# EFR32MG1B register map
File version: 5.4.0
Silicon Labs EFR32MG1B Cortex-M MCU
Registers are 32-bit, read-write, reset 0x0 unless marked. A register's access mark holds for its fields unless they carry their own. Offsets are from the block's base; lines under a group give offsets from that group; [hi:lo] are bit positions; {n}, {i} and the like mark numbered series; 'fields as' and 'values as' point back to an identical list; <NAME> marks a mode.

## Memory map
0x40000000 ACMP0 size 0x400
0x40000400 ACMP1 size 0x400
0x40002000 ADC0 size 0x400
0x40006000 IDAC0 size 0x400
0x4000A000 GPIO size 0x1000
0x4000C000 I2C0 size 0x400
0x40010000 USART0 size 0x400
0x40010400 USART1 size 0x400
0x40018000 TIMER0 size 0x400
0x40018400 TIMER1 size 0x400
0x4001C000 GPCRC size 0x400
0x4001E000 CRYOTIMER size 0x400
0x40042000 RTCC size 0x400
0x40046000 LETIMER0 size 0x400
0x4004A000 LEUART0 size 0x400
0x4004E000 PCNT0 size 0x400
0x40052000 WDOG0 size 0x400
0x400E0000 MSC size 0x800
0x400E1000 FPUEH size 0x400
0x400E2000 LDMA size 0x1000
0x400E3000 EMU size 0x400
0x400E4000 CMU size 0x400
0x400E5000 RMU size 0x400
0x400E6000 PRS size 0x400
0x400F0000 CRYPTO size 0x400

## Interrupts
0 EMU
2 WDOG0
8 LDMA
9 GPIO_EVEN (GPIO)
10 TIMER0
11 USART0_RX (USART0)
12 USART0_TX (USART0)
13 ACMP0 (ACMP0, ACMP1)
14 ADC0
15 IDAC0
16 I2C0
17 GPIO_ODD (GPIO)
18 TIMER1
19 USART1_RX (USART1)
20 USART1_TX (USART1)
21 LEUART0
22 PCNT0
23 CMU
24 MSC
25 CRYPTO
26 LETIMER0
29 RTCC
31 CRYOTIMER
33 FPUEH

## Further device data
name=Copyright 2017 Silicon Laboratories, Inc., flashBaseAddress=0x00000000, flashAccessTypes=rx, sramBaseAddress=0x20000000, sramAccessTypes=rwx

## RMU
Base 0x400E5000
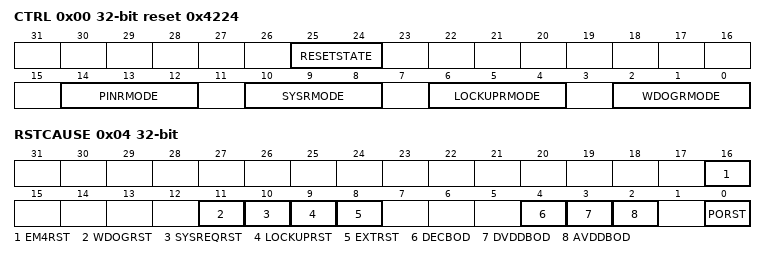
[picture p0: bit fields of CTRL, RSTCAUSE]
0x00 CTRL reset 0x4224 — Control Register
  [25:24] RESETSTATE — System Software Reset State
  [14:12] PINRMODE — PIN Reset Mode
    0=DISABLED (Reset request is blocked.); 1=LIMITED (The CRYOTIMER, DEBUGGER, RTCC, are not reset.); 2=EXTENDED (The CRYOTIMER, DEBUGGER are not reset. RTCC is reset.); 4=FULL (The entire device is reset except some EMU and RMU registers.)
  [10:8] SYSRMODE — Core Sysreset Reset Mode
    values as PINRMODE
  [6:4] LOCKUPRMODE — Core LOCKUP Reset Mode
    values as PINRMODE
  [2:0] WDOGRMODE — WDOG Reset Mode
    0=DISABLED (Reset request is blocked. This disable bit is redundant with enable/disable bit in WDOG); 1=LIMITED (The CRYOTIMER, DEBUGGER, RTCC, are not reset.); 2=EXTENDED (The CRYOTIMER, DEBUGGER are not reset. RTCC is reset.); 4=FULL (The entire device is reset except some EMU and RMU registers.)
0x04 RSTCAUSE ro — Reset Cause Register
  [16] EM4RST — EM4 Reset
  [11] WDOGRST — Watchdog Reset
  [10] SYSREQRST — System Request Reset
  [9] LOCKUPRST — LOCKUP Reset
  [8] EXTRST — External Pin Reset
  [4] DECBOD — Brown Out Detector Decouple Domain Reset
  [3] DVDDBOD — Brown Out Detector DVDD Reset
  [2] AVDDBOD — Brown Out Detector AVDD Reset
  [0] PORST — Power on Reset
0x08 CMD wo — Command Register
  [0] RCCLR — Reset Cause Clear
0x0C RST reset not defined — Reset Control Register
0x10 LOCK — Configuration Lock Register
  [15:0] LOCKKEY — Configuration Lock Key
    0=UNLOCKED; 1=LOCKED

## PRS
Base 0x400E6000
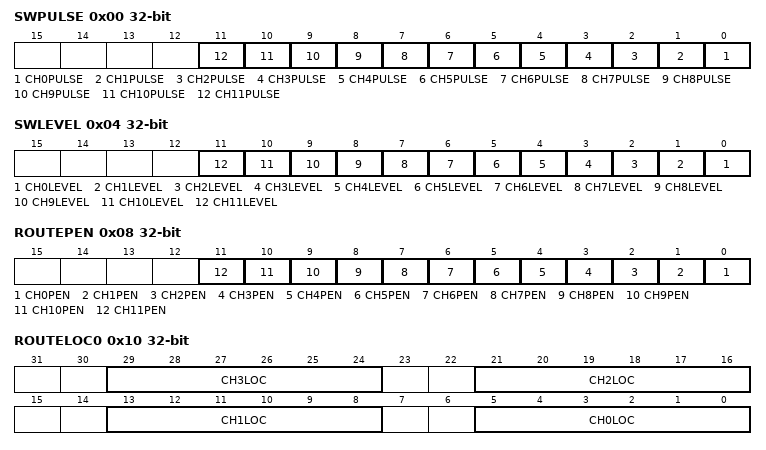
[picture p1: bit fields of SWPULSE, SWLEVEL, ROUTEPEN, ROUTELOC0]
0x00 SWPULSE wo — Software Pulse Register
  [n] CH{n}PULSE (n=0..11) — Channel {n} Pulse Generation
0x04 SWLEVEL — Software Level Register
  [n] CH{n}LEVEL (n=0..11) — Channel {n} Software Level
0x08 ROUTEPEN — I/O Routing Pin Enable Register
  [n] CH{n}PEN (n=0..11) — CH{n} Pin Enable
0x10 ROUTELOC0 — I/O Routing Location Register
  [29:24] CH3LOC — I/O Location
    {v}=LOC{v} (Location {v}) (v=0..14)
  [21:16] CH2LOC — I/O Location
    {v}=LOC{v} (Location {v}) (v=0..7)
  [13:8] CH1LOC — I/O Location
    {v}=LOC{v} (Location {v}) (v=0..7)
  [5:0] CH0LOC — I/O Location
    {v}=LOC{v} (Location {v}) (v=0..13)
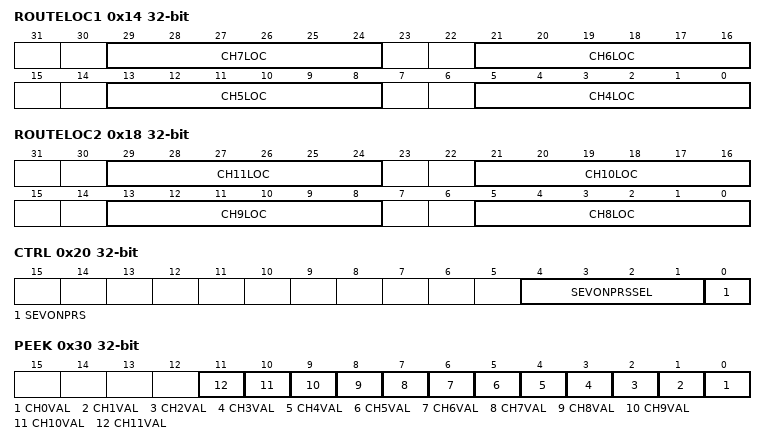
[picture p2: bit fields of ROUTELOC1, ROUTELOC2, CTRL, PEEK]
0x14 ROUTELOC1 — I/O Routing Location Register
  [29:24] CH7LOC — I/O Location
    {v}=LOC{v} (Location {v}) (v=0..10)
  [21:16] CH6LOC — I/O Location
    {v}=LOC{v} (Location {v}) (v=0..17)
  [13:8] CH5LOC — I/O Location
    {v}=LOC{v} (Location {v}) (v=0..6)
  [5:0] CH4LOC — I/O Location
    {v}=LOC{v} (Location {v}) (v=0..6)
0x18 ROUTELOC2 — I/O Routing Location Register
  [29:24] CH11LOC — I/O Location
    {v}=LOC{v} (Location {v}) (v=0..5)
  [21:16] CH10LOC — I/O Location
    {v}=LOC{v} (Location {v}) (v=0..5)
  [13:8] CH9LOC — I/O Location
    {v}=LOC{v} (Location {v}) (v=0..16)
  [5:0] CH8LOC — I/O Location
    {v}=LOC{v} (Location {v}) (v=0..10)
0x20 CTRL — Control Register
  [4:1] SEVONPRSSEL — SEVONPRS PRS Channel Select
    {v}=PRSCH{v} (PRS Channel {v} selected) (v=0..11)
  [0] SEVONPRS — Set Event on PRS
0x24 DMAREQ0 — DMA Request 0 Register
  [9:6] PRSSEL — DMA Request 0 PRS Channel Select
    {v}=PRSCH{v} (PRS Channel {v} selected) (v=0..11)
0x28 DMAREQ1 — DMA Request 1 Register
  [9:6] PRSSEL — DMA Request 1 PRS Channel Select
    {v}=PRSCH{v} (PRS Channel {v} selected) (v=0..11)
0x30 PEEK ro — PRS Channel Values
  [n] CH{n}VAL (n=0..11) — Channel {n} Current Value
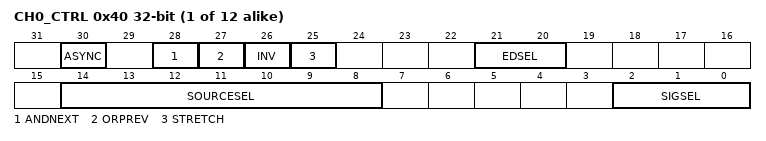
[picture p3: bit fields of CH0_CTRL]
{0x40+4i} CH{i}_CTRL (i=0..11) — Channel Control Register
  [30] ASYNC — Asynchronous Reflex
  [28] ANDNEXT
  [27] ORPREV — Or Previous
  [26] INV — Invert Channel
  [25] STRETCH — Stretch Channel Output
  [21:20] EDSEL — Edge Detect Select
    0=OFF (Signal is left as it is); 1=POSEDGE (A one HFCLK cycle pulse is generated for every positive edge of the incoming signal); 2=NEGEDGE (A one HFCLK clock cycle pulse is generated for every negative edge of the incoming signal); 3=BOTHEDGES (A one HFCLK clock cycle pulse is generated for every edge of the incoming signal)
  [14:8] SOURCESEL — Source Select
    0=NONE (No source selected); 1=PRSL (Peripheral Reflex System); 2=PRSH (Peripheral Reflex System); 6=ACMP0 (Analog Comparator 0); 7=ACMP1 (Analog Comparator 1); 8=ADC0 (Analog to Digital Converter 0); 16=USART0 (Universal Synchronous/Asynchronous Receiver/Transmitter 0); 17=USART1 (Universal Synchronous/Asynchronous Receiver/Transmitter 1); 28=TIMER0; 29=TIMER1; 41=RTCC (Real-Time Counter and Calendar); 48=GPIOL (General purpose Input/Output); 49=GPIOH (General purpose Input/Output); 52=LETIMER0 (Low Energy Timer 0); 54=PCNT0 (Pulse Counter 0); 60=CRYOTIMER; 61=CMU (Clock Management Unit); 67=CM4
  [2:0] SIGSEL — Signal Select
